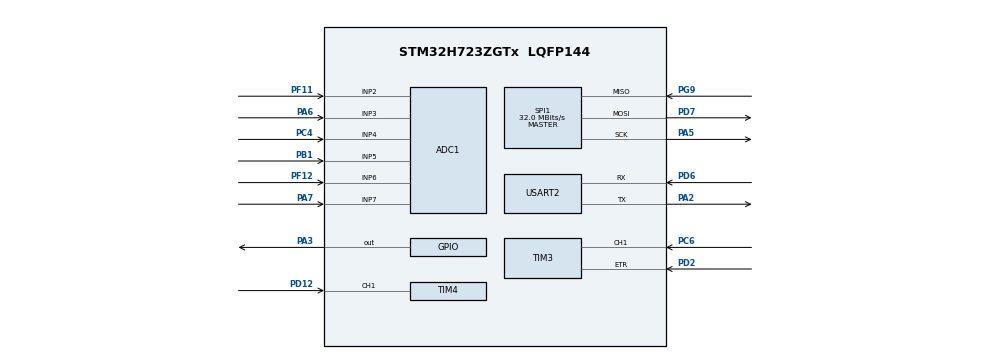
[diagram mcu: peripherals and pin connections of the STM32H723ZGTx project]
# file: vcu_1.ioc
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ADC1.Channel-0\#ChannelRegularConversion=ADC_CHANNEL_2
ADC1.NbrOfConversionFlag=1
ADC1.OffsetNumber-0\#ChannelRegularConversion=ADC_OFFSET_NONE
ADC1.OffsetSignedSaturation-0\#ChannelRegularConversion=DISABLE
ADC1.Rank-0\#ChannelRegularConversion=1
ADC1.SamplingTime-0\#ChannelRegularConversion=ADC_SAMPLETIME_1CYCLE_5
ADC1.master=1
CORTEX_M7.default_mode_Activation=1
Dma.ADC1.1.Direction=DMA_PERIPH_TO_MEMORY
Dma.ADC1.1.EventEnable=DISABLE
Dma.ADC1.1.FIFOMode=DMA_FIFOMODE_DISABLE
Dma.ADC1.1.Instance=DMA1_Stream1
Dma.ADC1.1.MemDataAlignment=DMA_MDATAALIGN_HALFWORD
Dma.ADC1.1.MemInc=DMA_MINC_ENABLE
Dma.ADC1.1.Mode=DMA_CIRCULAR
Dma.ADC1.1.PeriphDataAlignment=DMA_PDATAALIGN_HALFWORD
Dma.ADC1.1.PeriphInc=DMA_PINC_DISABLE
Dma.ADC1.1.Polarity=HAL_DMAMUX_REQ_GEN_RISING
Dma.ADC1.1.Priority=DMA_PRIORITY_LOW
Dma.ADC1.1.RequestNumber=1
Dma.ADC1.1.SignalID=NONE
Dma.ADC1.1.SyncEnable=DISABLE
Dma.ADC1.1.SyncPolarity=HAL_DMAMUX_SYNC_NO_EVENT
Dma.ADC1.1.SyncRequestNumber=1
Dma.ADC1.1.SyncSignalID=NONE
Dma.Request0=SPI1_RX
Dma.Request1=ADC1
Dma.SPI1_RX.0.Direction=DMA_PERIPH_TO_MEMORY
Dma.SPI1_RX.0.EventEnable=DISABLE
Dma.SPI1_RX.0.FIFOMode=DMA_FIFOMODE_DISABLE
Dma.SPI1_RX.0.Instance=DMA1_Stream0
Dma.SPI1_RX.0.MemDataAlignment=DMA_MDATAALIGN_BYTE
Dma.SPI1_RX.0.MemInc=DMA_MINC_ENABLE
Dma.SPI1_RX.0.Mode=DMA_NORMAL
Dma.SPI1_RX.0.PeriphDataAlignment=DMA_PDATAALIGN_BYTE
Dma.SPI1_RX.0.PeriphInc=DMA_PINC_DISABLE
Dma.SPI1_RX.0.Polarity=HAL_DMAMUX_REQ_GEN_RISING
Dma.SPI1_RX.0.Priority=DMA_PRIORITY_LOW
Dma.SPI1_RX.0.RequestNumber=1
Dma.SPI1_RX.0.SignalID=NONE
Dma.SPI1_RX.0.SyncEnable=DISABLE
Dma.SPI1_RX.0.SyncPolarity=HAL_DMAMUX_SYNC_NO_EVENT
Dma.SPI1_RX.0.SyncRequestNumber=1
Dma.SPI1_RX.0.SyncSignalID=NONE
Mcu.Family=STM32H7
Mcu.Name=STM32H723ZGTx
Mcu.Package=LQFP144
NVIC.ADC_IRQn=true\:0\:0\:false\:false\:true\:true\:true\:true
NVIC.DMA1_Stream0_IRQn=true\:0\:0\:false\:false\:true\:false\:true\:true
NVIC.DMA1_Stream1_IRQn=true\:0\:0\:false\:false\:true\:false\:true\:true
NVIC.PriorityGroup=NVIC_PRIORITYGROUP_4
NVIC.SPI1_IRQn=true\:0\:0\:false\:false\:true\:false\:true\:true
NVIC.TIM6_DAC_IRQn=true\:0\:0\:false\:false\:true\:true\:true\:true
PA2.Mode=Asynchronous
PA2.Signal=USART2_TX
PA3.Signal=GPIO_Output
PA5.Mode=Full_Duplex_Master
PA5.Signal=SPI1_SCK
PA6.Signal=ADCx_INP3
PA7.Signal=ADCx_INP7
PB1.Signal=ADCx_INP5
PC4.Signal=ADCx_INP4
PC6.Signal=S_TIM3_CH1
PD12.Signal=S_TIM4_CH1
PD2.Signal=S_TIM3_ETR
PD6.Mode=Asynchronous
PD6.Signal=USART2_RX
PD7.Mode=Full_Duplex_Master
PD7.Signal=SPI1_MOSI
PF11.Mode=IN2-Single-Ended
PF11.Signal=ADC1_INP2
PF12.Mode=IN6-Single-Ended
PF12.Signal=ADC1_INP6
PG9.Mode=Full_Duplex_Master
PG9.Signal=SPI1_MISO
ProjectManager.HeapSize=0x200
ProjectManager.StackSize=0x400
ProjectManager.TargetToolchain=STM32CubeIDE
RCC.ADCFreq_Value=38400000
RCC.APB1Freq_Value=64000000
RCC.APB2Freq_Value=64000000
RCC.APB3Freq_Value=64000000
RCC.APB4Freq_Value=64000000
RCC.CortexFreq_Value=64000000
RCC.DIVM1=4
RCC.DIVM2=4
RCC.DIVN1=12
RCC.DIVN2=12
RCC.DIVP2=5
RCC.DIVQ1=3
RCC.HCLKFreq_Value=64000000
RCC.PLL2FRACN=0
RCC.PLLFRACN=0
RCC.SYSCLKFreq_VALUE=64000000
RCC.USBFreq_Value=64000000
SH.ADCx_INP3.0=ADC1_INP3,IN3-Single-Ended
SH.ADCx_INP4.0=ADC1_INP4,IN4-Single-Ended
SH.ADCx_INP5.0=ADC1_INP5,IN5-Single-Ended
SH.ADCx_INP7.0=ADC1_INP7,IN7-Single-Ended
SH.S_TIM3_CH1.0=TIM3_CH1,Input_Capture1_from_TI1
SH.S_TIM3_ETR.0=TIM3_ETR,TriggerSource_ETR
SH.S_TIM4_CH1.0=TIM4_CH1,Input_Capture1_from_TI1
SPI1.CalculateBaudRate=32.0 MBits/s
SPI1.Direction=SPI_DIRECTION_2LINES
SPI1.Mode=SPI_MODE_MASTER
SPI1.VirtualType=VM_MASTER
TIM3.Channel-Input_Capture1_from_TI1=TIM_CHANNEL_1
TIM3.TIM_MasterOutputTrigger=TIM_TRGO_ENABLE
TIM4.Channel-Input_Capture1_from_TI1=TIM_CHANNEL_1
TIM4.TIM_MasterOutputTrigger=TIM_TRGO_ENABLE
TIM6.Period=1000-1
TIM6.Prescaler=64000-1
TIM7.Period=100-1
TIM7.Prescaler=64000-1
USART2.VirtualMode-Asynchronous=VM_ASYNC
VP_MEMORYMAP_VS_MEMORYMAP.Mode=CurAppReg
VP_TIM3_VS_ControllerModeTrigger.Mode=Trigger Mode
VP_TIM6_VS_ClockSourceINT.Mode=Enable_Timer
VP_TIM7_VS_ClockSourceINT.Mode=Enable_Timer
board=custom

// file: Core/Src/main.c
/* USER CODE BEGIN Header */
/**
  ******************************************************************************
  * @file           : main.c
  * @brief          : Main program body
  ******************************************************************************
  * @attention
  *
  * Copyright (c) 2025 STMicroelectronics.
  * All rights reserved.
  *
  * This software is licensed under terms that can be found in the LICENSE file
  * in the root directory of this software component.
  * If no LICENSE file comes with this software, it is provided AS-IS.
  *
  ******************************************************************************
  */
/* USER CODE END Header */
#include "main.h"

ADC_HandleTypeDef hadc1;
DMA_HandleTypeDef hdma_adc1;

SPI_HandleTypeDef hspi1;
DMA_HandleTypeDef hdma_spi1_rx;

TIM_HandleTypeDef htim3;
TIM_HandleTypeDef htim4;
TIM_HandleTypeDef htim6;
TIM_HandleTypeDef htim7;

UART_HandleTypeDef huart2;

void SystemClock_Config(void);
static void MPU_Config(void);
static void MX_GPIO_Init(void);
static void MX_DMA_Init(void);
static void MX_ADC1_Init(void);
static void MX_SPI1_Init(void);
static void MX_TIM3_Init(void);
static void MX_TIM4_Init(void);
static void MX_TIM6_Init(void);
static void MX_TIM7_Init(void);
static void MX_USART2_UART_Init(void);

int main(void)
{

  /* MPU Configuration--------------------------------------------------------*/
  MPU_Config();

  /* MCU Configuration--------------------------------------------------------*/

  /* Reset of all peripherals, Initializes the Flash interface and the Systick. */
  HAL_Init();

  /* Configure the system clock */
  SystemClock_Config();

  /* Initialize all configured peripherals */
  MX_GPIO_Init();
  MX_DMA_Init();
  MX_ADC1_Init();
  MX_SPI1_Init();
  MX_TIM3_Init();
  MX_TIM4_Init();
  MX_TIM6_Init();
  MX_TIM7_Init();
  MX_USART2_UART_Init();

  /* Infinite loop */
  /* USER CODE BEGIN WHILE */
  while (1)
  {
	  //Empty and boring like your life;
	  //VOID, Diddy, Epstein, Freakenstein;
	  //RTOS Biatch, No. off polls == Ur GF;
	  //Kill em Flacko
	  //I i i got that rocket on me

    /* USER CODE END WHILE */

  }
}

void SystemClock_Config(void)
{
  RCC_OscInitTypeDef RCC_OscInitStruct = {0};
  RCC_ClkInitTypeDef RCC_ClkInitStruct = {0};

  /** Supply configuration update enable
  */
  HAL_PWREx_ConfigSupply(PWR_LDO_SUPPLY);

  /** Configure the main internal regulator output voltage
  */
  __HAL_PWR_VOLTAGESCALING_CONFIG(PWR_REGULATOR_VOLTAGE_SCALE3);

  while(!__HAL_PWR_GET_FLAG(PWR_FLAG_VOSRDY)) {}

  /** Initializes the RCC Oscillators according to the specified parameters
  * in the RCC_OscInitTypeDef structure.
  */
  RCC_OscInitStruct.OscillatorType = RCC_OSCILLATORTYPE_HSI;
  RCC_OscInitStruct.HSIState = RCC_HSI_DIV1;
  RCC_OscInitStruct.HSICalibrationValue = 64;
  RCC_OscInitStruct.PLL.PLLState = RCC_PLL_ON;
  RCC_OscInitStruct.PLL.PLLSource = RCC_PLLSOURCE_HSI;
  RCC_OscInitStruct.PLL.PLLM = 4;
  RCC_OscInitStruct.PLL.PLLN = 12;
  RCC_OscInitStruct.PLL.PLLP = 2;
  RCC_OscInitStruct.PLL.PLLQ = 3;
  RCC_OscInitStruct.PLL.PLLR = 2;
  RCC_OscInitStruct.PLL.PLLRGE = RCC_PLL1VCIRANGE_3;
  RCC_OscInitStruct.PLL.PLLVCOSEL = RCC_PLL1VCOWIDE;
  RCC_OscInitStruct.PLL.PLLFRACN = 0;
  if (HAL_RCC_OscConfig(&RCC_OscInitStruct) != HAL_OK)
  {
    Error_Handler();
  }

  /** Initializes the CPU, AHB and APB buses clocks
  */
  RCC_ClkInitStruct.ClockType = RCC_CLOCKTYPE_HCLK|RCC_CLOCKTYPE_SYSCLK
                              |RCC_CLOCKTYPE_PCLK1|RCC_CLOCKTYPE_PCLK2
                              |RCC_CLOCKTYPE_D3PCLK1|RCC_CLOCKTYPE_D1PCLK1;
  RCC_ClkInitStruct.SYSCLKSource = RCC_SYSCLKSOURCE_HSI;
  RCC_ClkInitStruct.SYSCLKDivider = RCC_SYSCLK_DIV1;
  RCC_ClkInitStruct.AHBCLKDivider = RCC_HCLK_DIV1;
  RCC_ClkInitStruct.APB3CLKDivider = RCC_APB3_DIV1;
  RCC_ClkInitStruct.APB1CLKDivider = RCC_APB1_DIV1;
  RCC_ClkInitStruct.APB2CLKDivider = RCC_APB2_DIV1;
  RCC_ClkInitStruct.APB4CLKDivider = RCC_APB4_DIV1;

  if (HAL_RCC_ClockConfig(&RCC_ClkInitStruct, FLASH_LATENCY_1) != HAL_OK)
  {
    Error_Handler();
  }
}

static void MX_ADC1_Init(void)
{

  ADC_MultiModeTypeDef multimode = {0};
  ADC_ChannelConfTypeDef sConfig = {0};

  /** Common config
  */
  hadc1.Instance = ADC1;
  hadc1.Init.ClockPrescaler = ADC_CLOCK_ASYNC_DIV1;
  hadc1.Init.Resolution = ADC_RESOLUTION_16B;
  hadc1.Init.ScanConvMode = ADC_SCAN_DISABLE;
  hadc1.Init.EOCSelection = ADC_EOC_SINGLE_CONV;
  hadc1.Init.LowPowerAutoWait = DISABLE;
  hadc1.Init.ContinuousConvMode = DISABLE;
  hadc1.Init.NbrOfConversion = 1;
  hadc1.Init.DiscontinuousConvMode = DISABLE;
  hadc1.Init.ExternalTrigConv = ADC_SOFTWARE_START;
  hadc1.Init.ExternalTrigConvEdge = ADC_EXTERNALTRIGCONVEDGE_NONE;
  hadc1.Init.ConversionDataManagement = ADC_CONVERSIONDATA_DR;
  hadc1.Init.Overrun = ADC_OVR_DATA_PRESERVED;
  hadc1.Init.LeftBitShift = ADC_LEFTBITSHIFT_NONE;
  hadc1.Init.OversamplingMode = DISABLE;
  hadc1.Init.Oversampling.Ratio = 1;
  if (HAL_ADC_Init(&hadc1) != HAL_OK)
  {
    Error_Handler();
  }

  /** Configure the ADC multi-mode
  */
  multimode.Mode = ADC_MODE_INDEPENDENT;
  if (HAL_ADCEx_MultiModeConfigChannel(&hadc1, &multimode) != HAL_OK)
  {
    Error_Handler();
  }

  /** Configure Regular Channel
  */
  sConfig.Channel = ADC_CHANNEL_2;
  sConfig.Rank = ADC_REGULAR_RANK_1;
  sConfig.SamplingTime = ADC_SAMPLETIME_1CYCLE_5;
  sConfig.SingleDiff = ADC_SINGLE_ENDED;
  sConfig.OffsetNumber = ADC_OFFSET_NONE;
  sConfig.Offset = 0;
  sConfig.OffsetSignedSaturation = DISABLE;
  if (HAL_ADC_ConfigChannel(&hadc1, &sConfig) != HAL_OK)
  {
    Error_Handler();
  }

}

static void MX_SPI1_Init(void)
{

  /* SPI1 parameter configuration*/
  hspi1.Instance = SPI1;
  hspi1.Init.Mode = SPI_MODE_MASTER;
  hspi1.Init.Direction = SPI_DIRECTION_2LINES;
  hspi1.Init.DataSize = SPI_DATASIZE_4BIT;
  hspi1.Init.CLKPolarity = SPI_POLARITY_LOW;
  hspi1.Init.CLKPhase = SPI_PHASE_1EDGE;
  hspi1.Init.NSS = SPI_NSS_SOFT;
  hspi1.Init.BaudRatePrescaler = SPI_BAUDRATEPRESCALER_2;
  hspi1.Init.FirstBit = SPI_FIRSTBIT_MSB;
  hspi1.Init.TIMode = SPI_TIMODE_DISABLE;
  hspi1.Init.CRCCalculation = SPI_CRCCALCULATION_DISABLE;
  hspi1.Init.CRCPolynomial = 0x0;
  hspi1.Init.NSSPMode = SPI_NSS_PULSE_ENABLE;
  hspi1.Init.NSSPolarity = SPI_NSS_POLARITY_LOW;
  hspi1.Init.FifoThreshold = SPI_FIFO_THRESHOLD_01DATA;
  hspi1.Init.TxCRCInitializationPattern = SPI_CRC_INITIALIZATION_ALL_ZERO_PATTERN;
  hspi1.Init.RxCRCInitializationPattern = SPI_CRC_INITIALIZATION_ALL_ZERO_PATTERN;
  hspi1.Init.MasterSSIdleness = SPI_MASTER_SS_IDLENESS_00CYCLE;
  hspi1.Init.MasterInterDataIdleness = SPI_MASTER_INTERDATA_IDLENESS_00CYCLE;
  hspi1.Init.MasterReceiverAutoSusp = SPI_MASTER_RX_AUTOSUSP_DISABLE;
  hspi1.Init.MasterKeepIOState = SPI_MASTER_KEEP_IO_STATE_DISABLE;
  hspi1.Init.IOSwap = SPI_IO_SWAP_DISABLE;
  if (HAL_SPI_Init(&hspi1) != HAL_OK)
  {
    Error_Handler();
  }

}

static void MX_TIM3_Init(void)
{

  TIM_SlaveConfigTypeDef sSlaveConfig = {0};
  TIM_MasterConfigTypeDef sMasterConfig = {0};
  TIM_IC_InitTypeDef sConfigIC = {0};

  htim3.Instance = TIM3;
  htim3.Init.Prescaler = 0;
  htim3.Init.CounterMode = TIM_COUNTERMODE_UP;
  htim3.Init.Period = 65535;
  htim3.Init.ClockDivision = TIM_CLOCKDIVISION_DIV1;
  htim3.Init.AutoReloadPreload = TIM_AUTORELOAD_PRELOAD_DISABLE;
  if (HAL_TIM_Base_Init(&htim3) != HAL_OK)
  {
    Error_Handler();
  }
  if (HAL_TIM_IC_Init(&htim3) != HAL_OK)
  {
    Error_Handler();
  }
  sSlaveConfig.SlaveMode = TIM_SLAVEMODE_TRIGGER;
  sSlaveConfig.InputTrigger = TIM_TS_ETRF;
  sSlaveConfig.TriggerPolarity = TIM_TRIGGERPOLARITY_NONINVERTED;
  sSlaveConfig.TriggerPrescaler = TIM_TRIGGERPRESCALER_DIV1;
  sSlaveConfig.TriggerFilter = 0;
  if (HAL_TIM_SlaveConfigSynchro(&htim3, &sSlaveConfig) != HAL_OK)
  {
    Error_Handler();
  }
  sMasterConfig.MasterOutputTrigger = TIM_TRGO_ENABLE;
  sMasterConfig.MasterSlaveMode = TIM_MASTERSLAVEMODE_DISABLE;
  if (HAL_TIMEx_MasterConfigSynchronization(&htim3, &sMasterConfig) != HAL_OK)
  {
    Error_Handler();
  }
  sConfigIC.ICPolarity = TIM_INPUTCHANNELPOLARITY_RISING;
  sConfigIC.ICSelection = TIM_ICSELECTION_DIRECTTI;
  sConfigIC.ICPrescaler = TIM_ICPSC_DIV1;
  sConfigIC.ICFilter = 0;
  if (HAL_TIM_IC_ConfigChannel(&htim3, &sConfigIC, TIM_CHANNEL_1) != HAL_OK)
  {
    Error_Handler();
  }

}

static void MX_TIM4_Init(void)
{

  TIM_MasterConfigTypeDef sMasterConfig = {0};
  TIM_IC_InitTypeDef sConfigIC = {0};

  htim4.Instance = TIM4;
  htim4.Init.Prescaler = 0;
  htim4.Init.CounterMode = TIM_COUNTERMODE_UP;
  htim4.Init.Period = 65535;
  htim4.Init.ClockDivision = TIM_CLOCKDIVISION_DIV1;
  htim4.Init.AutoReloadPreload = TIM_AUTORELOAD_PRELOAD_DISABLE;
  if (HAL_TIM_IC_Init(&htim4) != HAL_OK)
  {
    Error_Handler();
  }
  sMasterConfig.MasterOutputTrigger = TIM_TRGO_ENABLE;
  sMasterConfig.MasterSlaveMode = TIM_MASTERSLAVEMODE_DISABLE;
  if (HAL_TIMEx_MasterConfigSynchronization(&htim4, &sMasterConfig) != HAL_OK)
  {
    Error_Handler();
  }
  sConfigIC.ICPolarity = TIM_INPUTCHANNELPOLARITY_RISING;
  sConfigIC.ICSelection = TIM_ICSELECTION_DIRECTTI;
  sConfigIC.ICPrescaler = TIM_ICPSC_DIV1;
  sConfigIC.ICFilter = 0;
  if (HAL_TIM_IC_ConfigChannel(&htim4, &sConfigIC, TIM_CHANNEL_1) != HAL_OK)
  {
    Error_Handler();
  }

}

static void MX_TIM6_Init(void)
{

  TIM_MasterConfigTypeDef sMasterConfig = {0};

  htim6.Instance = TIM6;
  htim6.Init.Prescaler = 64000-1;
  htim6.Init.CounterMode = TIM_COUNTERMODE_UP;
  htim6.Init.Period = 1000-1;
  htim6.Init.AutoReloadPreload = TIM_AUTORELOAD_PRELOAD_DISABLE;
  if (HAL_TIM_Base_Init(&htim6) != HAL_OK)
  {
    Error_Handler();
  }
  sMasterConfig.MasterOutputTrigger = TIM_TRGO_RESET;
  sMasterConfig.MasterSlaveMode = TIM_MASTERSLAVEMODE_DISABLE;
  if (HAL_TIMEx_MasterConfigSynchronization(&htim6, &sMasterConfig) != HAL_OK)
  {
    Error_Handler();
  }

}

static void MX_TIM7_Init(void)
{

  TIM_MasterConfigTypeDef sMasterConfig = {0};

  htim7.Instance = TIM7;
  htim7.Init.Prescaler = 64000-1;
  htim7.Init.CounterMode = TIM_COUNTERMODE_UP;
  htim7.Init.Period = 100-1;
  htim7.Init.AutoReloadPreload = TIM_AUTORELOAD_PRELOAD_DISABLE;
  if (HAL_TIM_Base_Init(&htim7) != HAL_OK)
  {
    Error_Handler();
  }
  sMasterConfig.MasterOutputTrigger = TIM_TRGO_RESET;
  sMasterConfig.MasterSlaveMode = TIM_MASTERSLAVEMODE_DISABLE;
  if (HAL_TIMEx_MasterConfigSynchronization(&htim7, &sMasterConfig) != HAL_OK)
  {
    Error_Handler();
  }

}

static void MX_USART2_UART_Init(void)
{

  huart2.Instance = USART2;
  huart2.Init.BaudRate = 115200;
  huart2.Init.WordLength = UART_WORDLENGTH_8B;
  huart2.Init.StopBits = UART_STOPBITS_1;
  huart2.Init.Parity = UART_PARITY_NONE;
  huart2.Init.Mode = UART_MODE_TX_RX;
  huart2.Init.HwFlowCtl = UART_HWCONTROL_NONE;
  huart2.Init.OverSampling = UART_OVERSAMPLING_16;
  huart2.Init.OneBitSampling = UART_ONE_BIT_SAMPLE_DISABLE;
  huart2.Init.ClockPrescaler = UART_PRESCALER_DIV1;
  huart2.AdvancedInit.AdvFeatureInit = UART_ADVFEATURE_NO_INIT;
  if (HAL_UART_Init(&huart2) != HAL_OK)
  {
    Error_Handler();
  }
  if (HAL_UARTEx_SetTxFifoThreshold(&huart2, UART_TXFIFO_THRESHOLD_1_8) != HAL_OK)
  {
    Error_Handler();
  }
  if (HAL_UARTEx_SetRxFifoThreshold(&huart2, UART_RXFIFO_THRESHOLD_1_8) != HAL_OK)
  {
    Error_Handler();
  }
  if (HAL_UARTEx_DisableFifoMode(&huart2) != HAL_OK)
  {
    Error_Handler();
  }

}

static void MX_DMA_Init(void)
{

  /* DMA controller clock enable */
  __HAL_RCC_DMA1_CLK_ENABLE();

  /* DMA interrupt init */
  /* DMA1_Stream0_IRQn interrupt configuration */
  HAL_NVIC_SetPriority(DMA1_Stream0_IRQn, 0, 0);
  HAL_NVIC_EnableIRQ(DMA1_Stream0_IRQn);
  /* DMA1_Stream1_IRQn interrupt configuration */
  HAL_NVIC_SetPriority(DMA1_Stream1_IRQn, 0, 0);
  HAL_NVIC_EnableIRQ(DMA1_Stream1_IRQn);

}

static void MX_GPIO_Init(void)
{
  GPIO_InitTypeDef GPIO_InitStruct = {0};

  /* GPIO Ports Clock Enable */
  __HAL_RCC_GPIOA_CLK_ENABLE();
  __HAL_RCC_GPIOC_CLK_ENABLE();
  __HAL_RCC_GPIOB_CLK_ENABLE();
  __HAL_RCC_GPIOF_CLK_ENABLE();
  __HAL_RCC_GPIOD_CLK_ENABLE();
  __HAL_RCC_GPIOG_CLK_ENABLE();

  /*Configure GPIO pin Output Level */
  HAL_GPIO_WritePin(GPIOA, GPIO_PIN_3, GPIO_PIN_RESET);

  /*Configure GPIO pin : PA3 */
  GPIO_InitStruct.Pin = GPIO_PIN_3;
  GPIO_InitStruct.Mode = GPIO_MODE_OUTPUT_PP;
  GPIO_InitStruct.Pull = GPIO_NOPULL;
  GPIO_InitStruct.Speed = GPIO_SPEED_FREQ_LOW;
  HAL_GPIO_Init(GPIOA, &GPIO_InitStruct);

}

 /* MPU Configuration */

void MPU_Config(void)
{
  MPU_Region_InitTypeDef MPU_InitStruct = {0};

  /* Disables the MPU */
  HAL_MPU_Disable();

  /** Initializes and configures the Region and the memory to be protected
  */
  MPU_InitStruct.Enable = MPU_REGION_ENABLE;
  MPU_InitStruct.Number = MPU_REGION_NUMBER0;
  MPU_InitStruct.BaseAddress = 0x0;
  MPU_InitStruct.Size = MPU_REGION_SIZE_4GB;
  MPU_InitStruct.SubRegionDisable = 0x87;
  MPU_InitStruct.TypeExtField = MPU_TEX_LEVEL0;
  MPU_InitStruct.AccessPermission = MPU_REGION_NO_ACCESS;
  MPU_InitStruct.DisableExec = MPU_INSTRUCTION_ACCESS_DISABLE;
  MPU_InitStruct.IsShareable = MPU_ACCESS_SHAREABLE;
  MPU_InitStruct.IsCacheable = MPU_ACCESS_NOT_CACHEABLE;
  MPU_InitStruct.IsBufferable = MPU_ACCESS_NOT_BUFFERABLE;

  HAL_MPU_ConfigRegion(&MPU_InitStruct);
  /* Enables the MPU */
  HAL_MPU_Enable(MPU_PRIVILEGED_DEFAULT);

}

void Error_Handler(void)
{
  __disable_irq();
  while (1)
  {
  }
}
